# jbr_MDR1986VE1T register map
Registers are 32-bit, access not given, no defined reset value unless marked. A register's access mark holds for its fields unless they carry their own. Addresses are absolute; registers are grouped by the start of their names; [hi:lo] are bit positions; {n}, {i} and the like mark numbered series.

## RAM
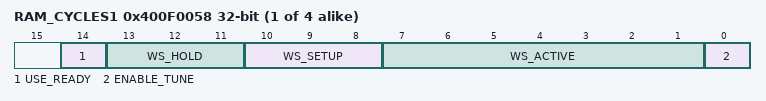
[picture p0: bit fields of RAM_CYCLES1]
{0x400F0054+4i} RAM_CYCLES{i} (i=1..4)
  [14] USE_READY, [13:11] WS_HOLD, [10:8] WS_SETUP, [7:1] WS_ACTIVE, [0] ENABLE_TUNE

## CAN1
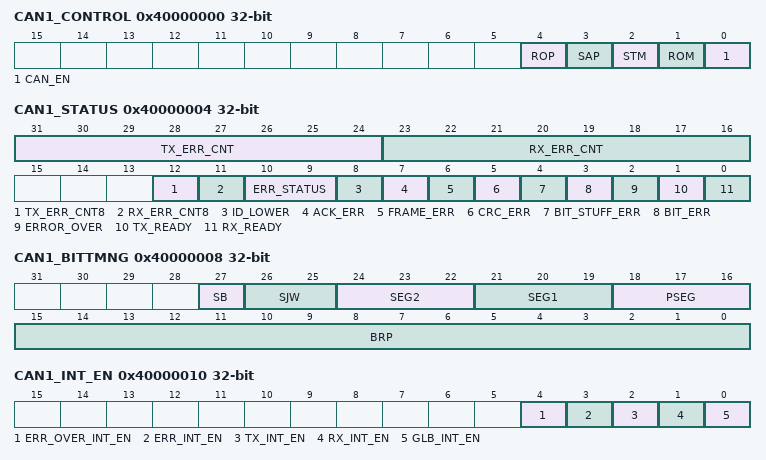
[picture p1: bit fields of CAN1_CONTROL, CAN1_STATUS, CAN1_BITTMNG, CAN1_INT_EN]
0x40000000 CAN1_CONTROL
  [4] ROP, [3] SAP, [2] STM, [1] ROM, [0] CAN_EN
0x40000004 CAN1_STATUS
  [31:24] TX_ERR_CNT, [23:16] RX_ERR_CNT, [12] TX_ERR_CNT8, [11] RX_ERR_CNT8, [10:9] ERR_STATUS, [8] ID_LOWER, [7] ACK_ERR, [6] FRAME_ERR, [5] CRC_ERR, [4] BIT_STUFF_ERR, [3] BIT_ERR, [2] ERROR_OVER, [1] TX_READY, [0] RX_READY
0x40000008 CAN1_BITTMNG
  [27] SB, [26:25] SJW, [24:22] SEG2, [21:19] SEG1, [18:16] PSEG, [15:0] BRP
0x40000010 CAN1_INT_EN
  [4] ERR_OVER_INT_EN, [3] ERR_INT_EN, [2] TX_INT_EN, [1] RX_INT_EN, [0] GLB_INT_EN
0x4000001C CAN1_OVER
  [7:0] ERROR_MAX
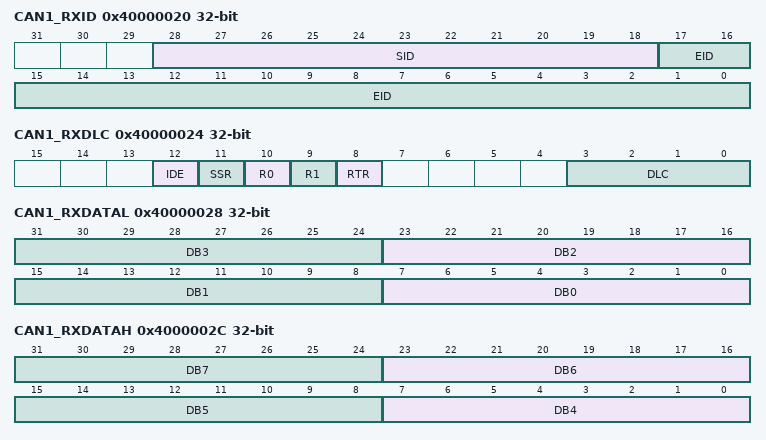
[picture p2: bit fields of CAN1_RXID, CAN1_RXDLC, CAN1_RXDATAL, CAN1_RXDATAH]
0x40000020 CAN1_RXID
  [28:18] SID, [17:0] EID
0x40000024 CAN1_RXDLC
  [12] IDE, [11] SSR, [10] R0, [9] R1, [8] RTR, [3:0] DLC
0x40000028 CAN1_RXDATAL
  [8n+7:8n] DB{n} (n=0..3)
0x4000002C CAN1_RXDATAH
  [8n-25:8n-32] DB{n} (n=4..7)
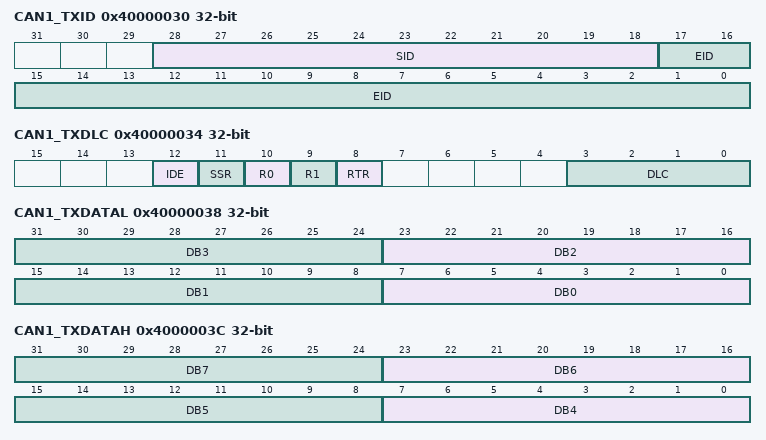
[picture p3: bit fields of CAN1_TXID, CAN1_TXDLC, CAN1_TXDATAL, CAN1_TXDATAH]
0x40000030 CAN1_TXID
  [28:18] SID, [17:0] EID
0x40000034 CAN1_TXDLC
  [12] IDE, [11] SSR, [10] R0, [9] R1, [8] RTR, [3:0] DLC
0x40000038 CAN1_TXDATAL
  [8n+7:8n] DB{n} (n=0..3)
0x4000003C CAN1_TXDATAH
  [8n-25:8n-32] DB{n} (n=4..7)
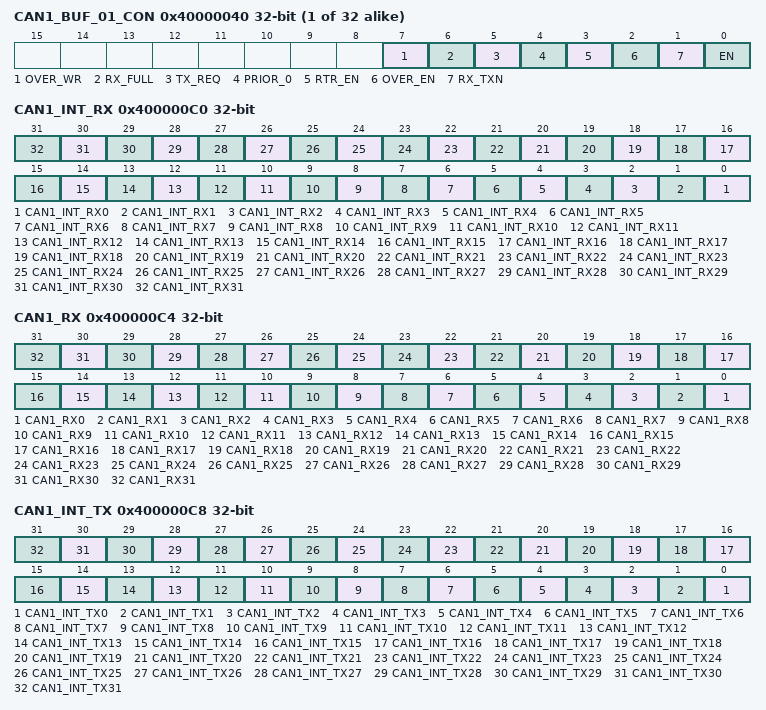
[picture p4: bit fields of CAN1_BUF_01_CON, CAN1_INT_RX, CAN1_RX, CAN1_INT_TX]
{0x4000003C+4i} CAN1_BUF_{i:02}_CON (i=1..32)
  [7] OVER_WR, [6] RX_FULL, [5] TX_REQ, [4] PRIOR_0, [3] RTR_EN, [2] OVER_EN, [1] RX_TXN, [0] EN
0x400000C0 CAN1_INT_RX
  [n] CAN1_INT_RX{n} (n=0..31)
0x400000C4 CAN1_RX
  [n] CAN1_RX{n} (n=0..31)
0x400000C8 CAN1_INT_TX
  [n] CAN1_INT_TX{n} (n=0..31)
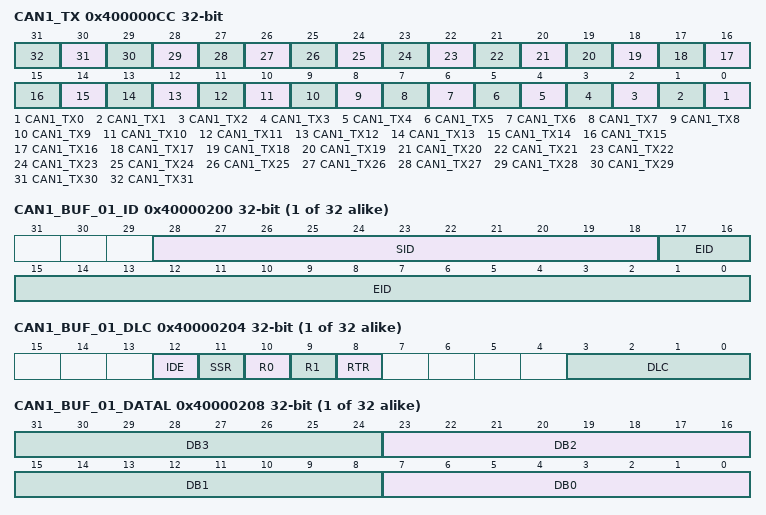
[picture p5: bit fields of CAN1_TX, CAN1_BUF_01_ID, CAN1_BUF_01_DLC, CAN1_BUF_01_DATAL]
0x400000CC CAN1_TX
  [n] CAN1_TX{n} (n=0..31)
{0x400001F0+0x10*i} CAN1_BUF_{i:02}_ID (i=1..32)
  [28:18] SID, [17:0] EID
{0x400001F4+0x10*i} CAN1_BUF_{i:02}_DLC (i=1..32)
  [12] IDE, [11] SSR, [10] R0, [9] R1, [8] RTR, [3:0] DLC
{0x400001F8+0x10*i} CAN1_BUF_{i:02}_DATAL (i=1..32)
  [8n+7:8n] DB{n} (n=0..3)
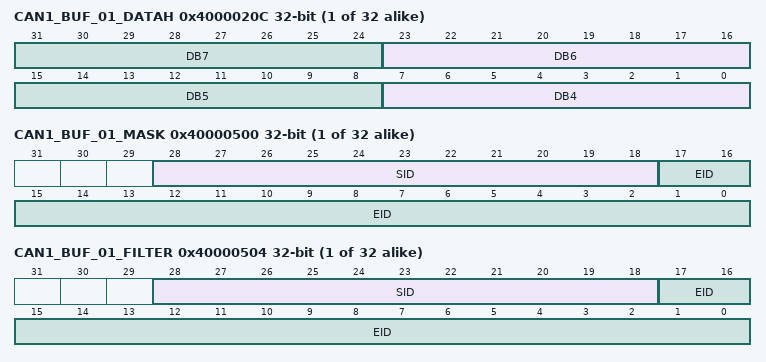
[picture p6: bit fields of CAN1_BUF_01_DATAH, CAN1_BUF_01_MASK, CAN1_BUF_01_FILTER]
{0x400001FC+0x10*i} CAN1_BUF_{i:02}_DATAH (i=1..32)
  [8n-25:8n-32] DB{n} (n=4..7)
{0x400004F8+8i} CAN1_BUF_{i:02}_MASK (i=1..32)
  [28:18] SID, [17:0] EID
{0x400004FC+8i} CAN1_BUF_{i:02}_FILTER (i=1..32)
  [28:18] SID, [17:0] EID

## CAN2
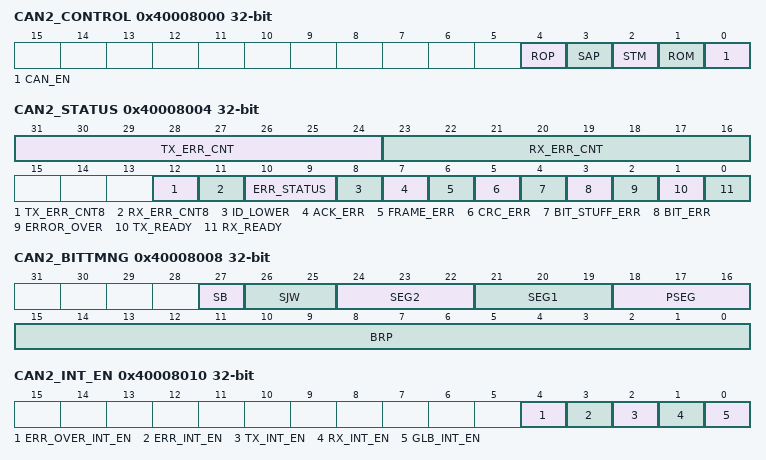
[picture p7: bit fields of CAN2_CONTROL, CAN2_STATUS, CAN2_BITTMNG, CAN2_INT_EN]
0x40008000 CAN2_CONTROL
  [4] ROP, [3] SAP, [2] STM, [1] ROM, [0] CAN_EN
0x40008004 CAN2_STATUS
  [31:24] TX_ERR_CNT, [23:16] RX_ERR_CNT, [12] TX_ERR_CNT8, [11] RX_ERR_CNT8, [10:9] ERR_STATUS, [8] ID_LOWER, [7] ACK_ERR, [6] FRAME_ERR, [5] CRC_ERR, [4] BIT_STUFF_ERR, [3] BIT_ERR, [2] ERROR_OVER, [1] TX_READY, [0] RX_READY
0x40008008 CAN2_BITTMNG
  [27] SB, [26:25] SJW, [24:22] SEG2, [21:19] SEG1, [18:16] PSEG, [15:0] BRP
0x40008010 CAN2_INT_EN
  [4] ERR_OVER_INT_EN, [3] ERR_INT_EN, [2] TX_INT_EN, [1] RX_INT_EN, [0] GLB_INT_EN
0x4000801C CAN2_OVER
  [7:0] ERROR_MAX
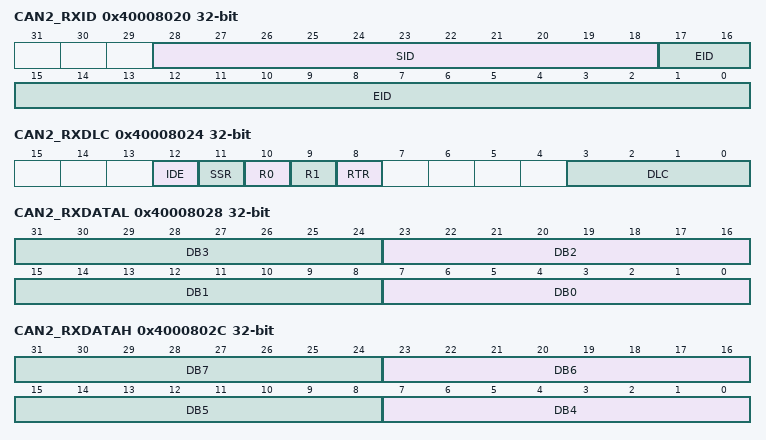
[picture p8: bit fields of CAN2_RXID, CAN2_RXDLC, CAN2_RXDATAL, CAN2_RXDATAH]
0x40008020 CAN2_RXID
  [28:18] SID, [17:0] EID
0x40008024 CAN2_RXDLC
  [12] IDE, [11] SSR, [10] R0, [9] R1, [8] RTR, [3:0] DLC
0x40008028 CAN2_RXDATAL
  [8n+7:8n] DB{n} (n=0..3)
0x4000802C CAN2_RXDATAH
  [8n-25:8n-32] DB{n} (n=4..7)
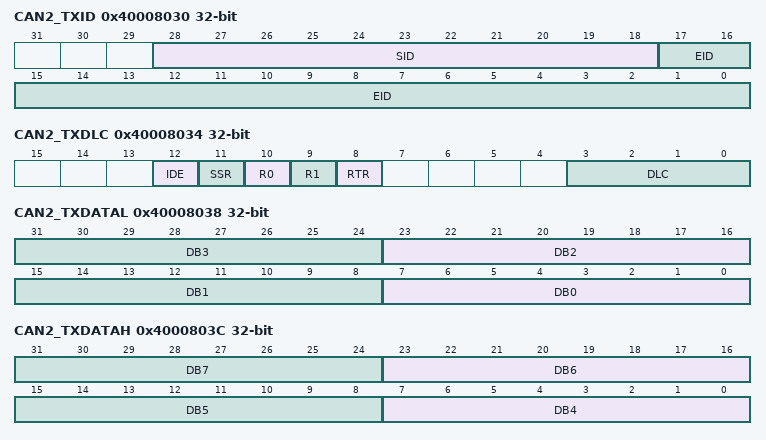
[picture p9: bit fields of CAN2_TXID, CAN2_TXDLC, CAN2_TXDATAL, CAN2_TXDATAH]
0x40008030 CAN2_TXID
  [28:18] SID, [17:0] EID
0x40008034 CAN2_TXDLC
  [12] IDE, [11] SSR, [10] R0, [9] R1, [8] RTR, [3:0] DLC
0x40008038 CAN2_TXDATAL
  [8n+7:8n] DB{n} (n=0..3)
0x4000803C CAN2_TXDATAH
  [8n-25:8n-32] DB{n} (n=4..7)
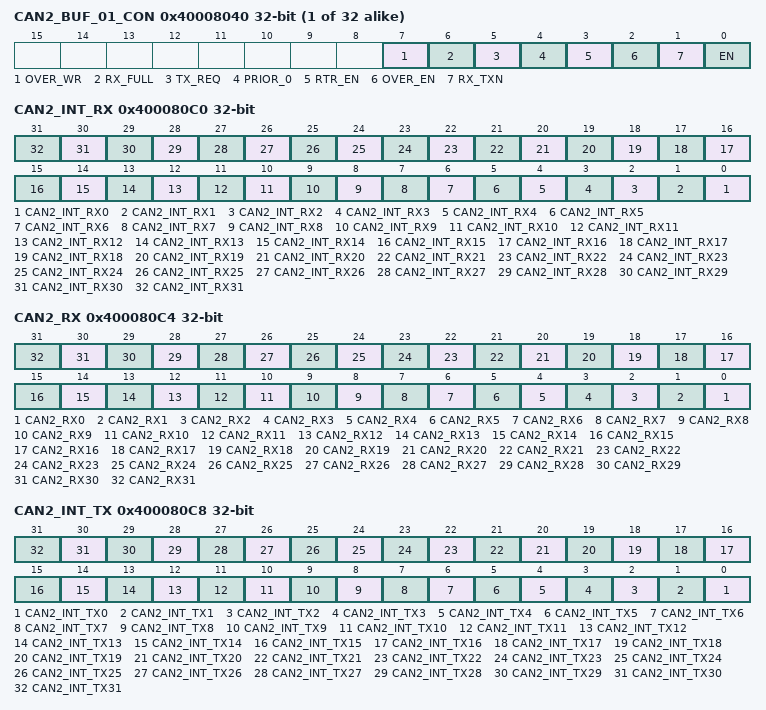
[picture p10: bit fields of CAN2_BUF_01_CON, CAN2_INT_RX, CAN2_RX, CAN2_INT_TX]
{0x4000803C+4i} CAN2_BUF_{i:02}_CON (i=1..32)
  [7] OVER_WR, [6] RX_FULL, [5] TX_REQ, [4] PRIOR_0, [3] RTR_EN, [2] OVER_EN, [1] RX_TXN, [0] EN
0x400080C0 CAN2_INT_RX
  [n] CAN2_INT_RX{n} (n=0..31)
0x400080C4 CAN2_RX
  [n] CAN2_RX{n} (n=0..31)
0x400080C8 CAN2_INT_TX
  [n] CAN2_INT_TX{n} (n=0..31)
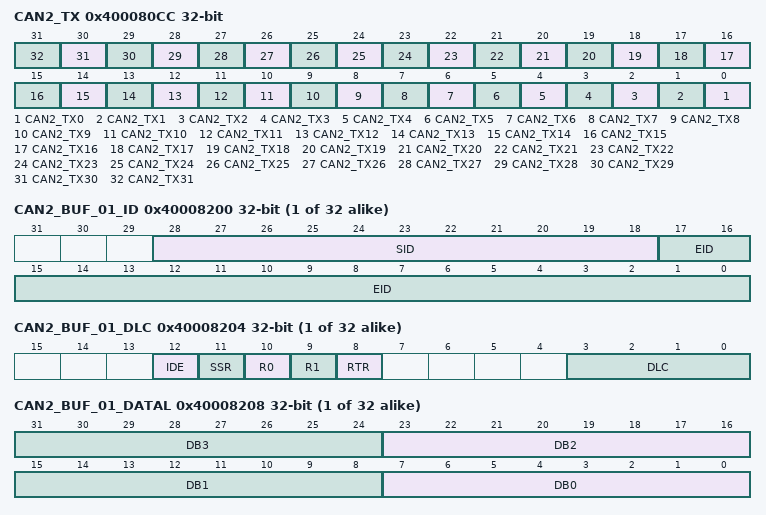
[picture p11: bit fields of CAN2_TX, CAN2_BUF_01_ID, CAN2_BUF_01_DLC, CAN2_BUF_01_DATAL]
0x400080CC CAN2_TX
  [n] CAN2_TX{n} (n=0..31)
{0x400081F0+0x10*i} CAN2_BUF_{i:02}_ID (i=1..32)
  [28:18] SID, [17:0] EID
{0x400081F4+0x10*i} CAN2_BUF_{i:02}_DLC (i=1..32)
  [12] IDE, [11] SSR, [10] R0, [9] R1, [8] RTR, [3:0] DLC
{0x400081F8+0x10*i} CAN2_BUF_{i:02}_DATAL (i=1..32)
  [8n+7:8n] DB{n} (n=0..3)
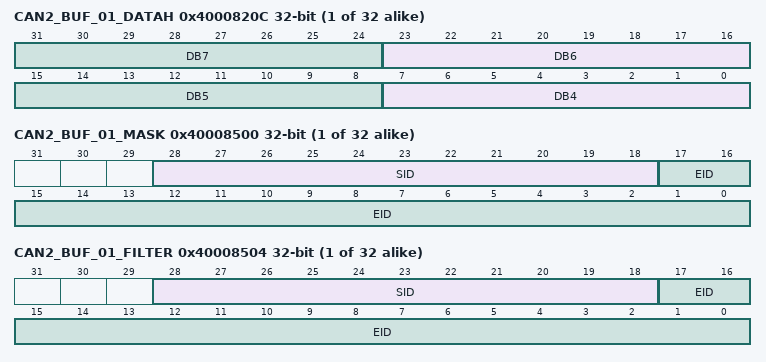
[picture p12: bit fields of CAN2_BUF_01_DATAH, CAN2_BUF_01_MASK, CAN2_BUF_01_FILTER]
{0x400081FC+0x10*i} CAN2_BUF_{i:02}_DATAH (i=1..32)
  [8n-25:8n-32] DB{n} (n=4..7)
0x40008320 CAN2_BUF_29_ID
{0x400084F8+8i} CAN2_BUF_{i:02}_MASK (i=1..32)
  [28:18] SID, [17:0] EID
{0x400084FC+8i} CAN2_BUF_{i:02}_FILTER (i=1..32)
  [28:18] SID, [17:0] EID
